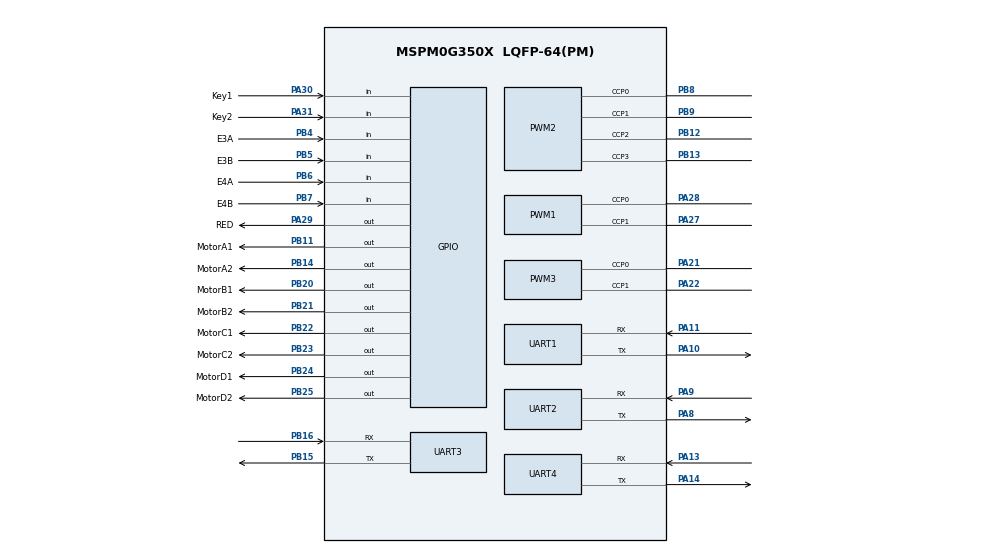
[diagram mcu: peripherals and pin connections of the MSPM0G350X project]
/**
 * @cliArgs --device "MSPM0G350X" --package "LQFP-64(PM)" --part "Default" --product "mspm0_sdk@2.01.00.03"
 * @versions {"tool":"1.20.0+3587"}
 */

/**
 * Import the modules used in this configuration.
 */
const GPIO    = scripting.addModule("/ti/driverlib/GPIO", {}, false);
const GPIO1   = GPIO.addInstance();
const GPIO2   = GPIO.addInstance();
const GPIO3   = GPIO.addInstance();
const GPIO4   = GPIO.addInstance();
const GPIO5   = GPIO.addInstance();
const GPIO6   = GPIO.addInstance();
const GPIO7   = GPIO.addInstance();
const PWM     = scripting.addModule("/ti/driverlib/PWM", {}, false);
const PWM1    = PWM.addInstance();
const PWM2    = PWM.addInstance();
const PWM3    = PWM.addInstance();
const SYSCTL  = scripting.addModule("/ti/driverlib/SYSCTL");
const SYSTICK = scripting.addModule("/ti/driverlib/SYSTICK");
const TIMER   = scripting.addModule("/ti/driverlib/TIMER", {}, false);
const TIMER1  = TIMER.addInstance();
const UART    = scripting.addModule("/ti/driverlib/UART", {}, false);
const UART1   = UART.addInstance();
const UART2   = UART.addInstance();
const UART3   = UART.addInstance();
const UART4   = UART.addInstance();

/**
 * Write custom configuration values to the imported modules.
 */
const divider9       = system.clockTree["UDIV"];
divider9.divideValue = 2;

const gate7  = system.clockTree["MFCLKGATE"];
gate7.enable = true;

const mux4       = system.clockTree["EXHFMUX"];
mux4.inputSelect = "EXHFMUX_XTAL";

const mux8       = system.clockTree["HSCLKMUX"];
mux8.inputSelect = "HSCLKMUX_SYSPLL2X";

const mux12       = system.clockTree["SYSPLLMUX"];
mux12.inputSelect = "zSYSPLLMUX_HFCLK";

const pinFunction4        = system.clockTree["HFXT"];
pinFunction4.inputFreq    = 40;
pinFunction4.enable       = true;
pinFunction4.HFXTStartup  = 10;
pinFunction4.HFCLKMonitor = true;

GPIO1.$name                          = "GPIO_RGB";
GPIO1.port                           = "PORTA";
GPIO1.associatedPins[0].$name        = "RED";
GPIO1.associatedPins[0].initialValue = "SET";
GPIO1.associatedPins[0].assignedPin  = "29";
GPIO1.associatedPins[0].pin.$assign  = "PA29";

const Board = scripting.addModule("/ti/driverlib/Board", {}, false);

GPIO2.$name                         = "OLED";
GPIO2.port                          = "PORTA";
GPIO2.associatedPins.create(2);
GPIO2.associatedPins[0].$name       = "OLED_SCL";
GPIO2.associatedPins[0].assignedPin = "16";
GPIO2.associatedPins[1].$name       = "OLED_SDA";
GPIO2.associatedPins[1].assignedPin = "15";

GPIO3.$name                         = "Motor";
GPIO3.port                          = "PORTB";
GPIO3.associatedPins.create(8);
GPIO3.associatedPins[0].$name       = "MotorA1";
GPIO3.associatedPins[0].assignedPin = "11";
GPIO3.associatedPins[0].pin.$assign = "PB11";
GPIO3.associatedPins[1].$name       = "MotorA2";
GPIO3.associatedPins[1].assignedPin = "14";
GPIO3.associatedPins[1].pin.$assign = "PB14";
GPIO3.associatedPins[2].$name       = "MotorC1";
GPIO3.associatedPins[2].assignedPin = "22";
GPIO3.associatedPins[2].pin.$assign = "PB22";
GPIO3.associatedPins[3].$name       = "MotorB2";
GPIO3.associatedPins[3].assignedPin = "21";
GPIO3.associatedPins[3].pin.$assign = "PB21";
GPIO3.associatedPins[4].$name       = "MotorB1";
GPIO3.associatedPins[4].assignedPin = "20";
GPIO3.associatedPins[4].pin.$assign = "PB20";
GPIO3.associatedPins[5].$name       = "MotorC2";
GPIO3.associatedPins[5].assignedPin = "23";
GPIO3.associatedPins[5].pin.$assign = "PB23";
GPIO3.associatedPins[6].$name       = "MotorD1";
GPIO3.associatedPins[6].assignedPin = "24";
GPIO3.associatedPins[6].pin.$assign = "PB24";
GPIO3.associatedPins[7].$name       = "MotorD2";
GPIO3.associatedPins[7].assignedPin = "25";
GPIO3.associatedPins[7].pin.$assign = "PB25";

GPIO4.$name                               = "ENCODER";
GPIO4.port                                = "PORTB";
GPIO4.associatedPins.create(4);
GPIO4.associatedPins[0].direction         = "INPUT";
GPIO4.associatedPins[0].interruptEn       = true;
GPIO4.associatedPins[0].interruptPriority = "0";
GPIO4.associatedPins[0].polarity          = "RISE";
GPIO4.associatedPins[0].$name             = "E3A";
GPIO4.associatedPins[0].assignedPin       = "4";
GPIO4.associatedPins[0].internalResistor  = "PULL_UP";
GPIO4.associatedPins[0].pin.$assign       = "PB4";
GPIO4.associatedPins[1].$name             = "E3B";
GPIO4.associatedPins[1].direction         = "INPUT";
GPIO4.associatedPins[1].interruptEn       = true;
GPIO4.associatedPins[1].interruptPriority = "0";
GPIO4.associatedPins[1].polarity          = "RISE";
GPIO4.associatedPins[1].assignedPin       = "5";
GPIO4.associatedPins[1].internalResistor  = "PULL_UP";
GPIO4.associatedPins[1].pin.$assign       = "PB5";
GPIO4.associatedPins[2].$name             = "E4A";
GPIO4.associatedPins[2].direction         = "INPUT";
GPIO4.associatedPins[2].assignedPin       = "6";
GPIO4.associatedPins[2].interruptEn       = true;
GPIO4.associatedPins[2].interruptPriority = "0";
GPIO4.associatedPins[2].polarity          = "RISE";
GPIO4.associatedPins[2].internalResistor  = "PULL_UP";
GPIO4.associatedPins[2].pin.$assign       = "PB6";
GPIO4.associatedPins[3].$name             = "E4B";
GPIO4.associatedPins[3].direction         = "INPUT";
GPIO4.associatedPins[3].assignedPin       = "7";
GPIO4.associatedPins[3].interruptEn       = true;
GPIO4.associatedPins[3].interruptPriority = "0";
GPIO4.associatedPins[3].polarity          = "RISE";
GPIO4.associatedPins[3].internalResistor  = "PULL_UP";
GPIO4.associatedPins[3].pin.$assign       = "PB7";

GPIO5.$name                              = "sensor";
GPIO5.associatedPins.create(8);
GPIO5.associatedPins[0].$name            = "D1";
GPIO5.associatedPins[0].direction        = "INPUT";
GPIO5.associatedPins[0].assignedPort     = "PORTB";
GPIO5.associatedPins[0].assignedPin      = "0";
GPIO5.associatedPins[0].internalResistor = "PULL_DOWN";
GPIO5.associatedPins[1].$name            = "D2";
GPIO5.associatedPins[1].assignedPort     = "PORTB";
GPIO5.associatedPins[1].assignedPin      = "27";
GPIO5.associatedPins[1].direction        = "INPUT";
GPIO5.associatedPins[1].internalResistor = "PULL_DOWN";
GPIO5.associatedPins[2].$name            = "D3";
GPIO5.associatedPins[2].direction        = "INPUT";
GPIO5.associatedPins[2].assignedPort     = "PORTB";
GPIO5.associatedPins[2].assignedPin      = "26";
GPIO5.associatedPins[2].internalResistor = "PULL_DOWN";
GPIO5.associatedPins[3].$name            = "D4";
GPIO5.associatedPins[3].direction        = "INPUT";
GPIO5.associatedPins[3].assignedPort     = "PORTA";
GPIO5.associatedPins[3].assignedPin      = "26";
GPIO5.associatedPins[3].internalResistor = "PULL_DOWN";
GPIO5.associatedPins[4].$name            = "D5";
GPIO5.associatedPins[4].direction        = "INPUT";
GPIO5.associatedPins[4].assignedPort     = "PORTA";
GPIO5.associatedPins[4].assignedPin      = "25";
GPIO5.associatedPins[4].internalResistor = "PULL_DOWN";
GPIO5.associatedPins[5].$name            = "D6";
GPIO5.associatedPins[5].direction        = "INPUT";
GPIO5.associatedPins[5].assignedPort     = "PORTA";
GPIO5.associatedPins[5].assignedPin      = "24";
GPIO5.associatedPins[5].internalResistor = "PULL_DOWN";
GPIO5.associatedPins[6].$name            = "D7";
GPIO5.associatedPins[6].direction        = "INPUT";
GPIO5.associatedPins[6].assignedPort     = "PORTA";
GPIO5.associatedPins[6].assignedPin      = "12";
GPIO5.associatedPins[6].internalResistor = "PULL_DOWN";
GPIO5.associatedPins[7].$name            = "D8";
GPIO5.associatedPins[7].direction        = "INPUT";
GPIO5.associatedPins[7].assignedPort     = "PORTA";
GPIO5.associatedPins[7].assignedPin      = "7";
GPIO5.associatedPins[7].internalResistor = "PULL_DOWN";

GPIO6.$name                              = "Key";
GPIO6.associatedPins.create(6);
GPIO6.associatedPins[0].$name            = "Key1";
GPIO6.associatedPins[0].direction        = "INPUT";
GPIO6.associatedPins[0].internalResistor = "PULL_UP";
GPIO6.associatedPins[0].assignedPin      = "30";
GPIO6.associatedPins[0].pin.$assign      = "PA30";
GPIO6.associatedPins[1].$name            = "Key2";
GPIO6.associatedPins[1].direction        = "INPUT";
GPIO6.associatedPins[1].assignedPin      = "31";
GPIO6.associatedPins[1].internalResistor = "PULL_UP";
GPIO6.associatedPins[1].pin.$assign      = "PA31";
GPIO6.associatedPins[2].$name            = "key3";
GPIO6.associatedPins[2].direction        = "INPUT";
GPIO6.associatedPins[2].internalResistor = "PULL_UP";
GPIO6.associatedPins[2].assignedPort     = "PORTB";
GPIO6.associatedPins[2].assignedPin      = "10";
GPIO6.associatedPins[3].$name            = "key4";
GPIO6.associatedPins[3].direction        = "INPUT";
GPIO6.associatedPins[3].internalResistor = "PULL_UP";
GPIO6.associatedPins[3].assignedPort     = "PORTB";
GPIO6.associatedPins[3].assignedPin      = "17";
GPIO6.associatedPins[4].$name            = "key5";
GPIO6.associatedPins[4].direction        = "INPUT";
GPIO6.associatedPins[4].assignedPort     = "PORTB";
GPIO6.associatedPins[4].assignedPin      = "18";
GPIO6.associatedPins[4].internalResistor = "PULL_UP";
GPIO6.associatedPins[5].$name            = "key6";
GPIO6.associatedPins[5].direction        = "INPUT";
GPIO6.associatedPins[5].internalResistor = "PULL_UP";
GPIO6.associatedPins[5].assignedPort     = "PORTB";
GPIO6.associatedPins[5].assignedPin      = "19";

GPIO7.$name                         = "BUZZER";
GPIO7.port                          = "PORTA";
GPIO7.associatedPins[0].$name       = "buzzer";
GPIO7.associatedPins[0].assignedPin = "2";

PWM1.$name                              = "PWM";
PWM1.timerStartTimer                    = true;
PWM1.clockDivider                       = 8;
PWM1.timerCount                         = 20000;
PWM1.peripheral.$assign                 = "TIMG7";
PWM1.peripheral.ccp0Pin.$assign         = "PA28";
PWM1.peripheral.ccp1Pin.$assign         = "PA27";
PWM1.PWM_CHANNEL_0.$name                = "ti_driverlib_pwm_PWMTimerCC0";
PWM1.PWM_CHANNEL_0.invert               = true;
PWM1.PWM_CHANNEL_1.$name                = "ti_driverlib_pwm_PWMTimerCC1";
PWM1.PWM_CHANNEL_1.invert               = true;
PWM1.ccp0PinConfig.$name                = "ti_driverlib_gpio_GPIOPinGeneric0";
PWM1.ccp0PinConfig.direction            = scripting.forceWrite("OUTPUT");
PWM1.ccp0PinConfig.hideOutputInversion  = scripting.forceWrite(false);
PWM1.ccp0PinConfig.onlyInternalResistor = scripting.forceWrite(false);
PWM1.ccp0PinConfig.passedPeripheralType = scripting.forceWrite("Digital");
PWM1.ccp1PinConfig.$name                = "ti_driverlib_gpio_GPIOPinGeneric1";
PWM1.ccp1PinConfig.direction            = scripting.forceWrite("OUTPUT");
PWM1.ccp1PinConfig.hideOutputInversion  = scripting.forceWrite(false);
PWM1.ccp1PinConfig.onlyInternalResistor = scripting.forceWrite(false);
PWM1.ccp1PinConfig.passedPeripheralType = scripting.forceWrite("Digital");

PWM2.$name                              = "Motor_PWM";
PWM2.ccIndex                            = [0,1,2,3];
PWM2.clockDivider                       = 8;
PWM2.clockPrescale                      = 2;
PWM2.timerStartTimer                    = true;
PWM2.peripheral.$assign                 = "TIMA0";
PWM2.peripheral.ccp0Pin.$assign         = "PB8";
PWM2.peripheral.ccp1Pin.$assign         = "PB9";
PWM2.peripheral.ccp2Pin.$assign         = "PB12";
PWM2.peripheral.ccp3Pin.$assign         = "PB13";
PWM2.PWM_CHANNEL_0.$name                = "ti_driverlib_pwm_PWMTimerCC2";
PWM2.PWM_CHANNEL_0.invert               = true;
PWM2.PWM_CHANNEL_1.$name                = "ti_driverlib_pwm_PWMTimerCC3";
PWM2.PWM_CHANNEL_1.invert               = true;
PWM2.ccp0PinConfig.direction            = scripting.forceWrite("OUTPUT");
PWM2.ccp0PinConfig.hideOutputInversion  = scripting.forceWrite(false);
PWM2.ccp0PinConfig.onlyInternalResistor = scripting.forceWrite(false);
PWM2.ccp0PinConfig.passedPeripheralType = scripting.forceWrite("Digital");
PWM2.ccp0PinConfig.$name                = "ti_driverlib_gpio_GPIOPinGeneric10";
PWM2.ccp1PinConfig.direction            = scripting.forceWrite("OUTPUT");
PWM2.ccp1PinConfig.hideOutputInversion  = scripting.forceWrite(false);
PWM2.ccp1PinConfig.onlyInternalResistor = scripting.forceWrite(false);
PWM2.ccp1PinConfig.passedPeripheralType = scripting.forceWrite("Digital");
PWM2.ccp1PinConfig.$name                = "ti_driverlib_gpio_GPIOPinGeneric11";
PWM2.PWM_CHANNEL_2.$name                = "ti_driverlib_pwm_PWMTimerCC4";
PWM2.PWM_CHANNEL_2.invert               = true;
PWM2.PWM_CHANNEL_3.$name                = "ti_driverlib_pwm_PWMTimerCC5";
PWM2.PWM_CHANNEL_3.invert               = true;
PWM2.ccp2PinConfig.$name                = "ti_driverlib_gpio_GPIOPinGeneric12";
PWM2.ccp3PinConfig.$name                = "ti_driverlib_gpio_GPIOPinGeneric13";

PWM3.$name                              = "Servo_PWM";
PWM3.clockDivider                       = 8;
PWM3.timerStartTimer                    = true;
PWM3.timerCount                         = 20000;
PWM3.peripheral.$assign                 = "TIMG6";
PWM3.peripheral.ccp0Pin.$assign         = "PA21";
PWM3.peripheral.ccp1Pin.$assign         = "PA22";
PWM3.PWM_CHANNEL_0.$name                = "ti_driverlib_pwm_PWMTimerCC6";
PWM3.PWM_CHANNEL_0.invert               = true;
PWM3.PWM_CHANNEL_1.$name                = "ti_driverlib_pwm_PWMTimerCC7";
PWM3.PWM_CHANNEL_1.invert               = true;
PWM3.ccp0PinConfig.direction            = scripting.forceWrite("OUTPUT");
PWM3.ccp0PinConfig.hideOutputInversion  = scripting.forceWrite(false);
PWM3.ccp0PinConfig.onlyInternalResistor = scripting.forceWrite(false);
PWM3.ccp0PinConfig.passedPeripheralType = scripting.forceWrite("Digital");
PWM3.ccp0PinConfig.$name                = "ti_driverlib_gpio_GPIOPinGeneric14";
PWM3.ccp1PinConfig.direction            = scripting.forceWrite("OUTPUT");
PWM3.ccp1PinConfig.hideOutputInversion  = scripting.forceWrite(false);
PWM3.ccp1PinConfig.onlyInternalResistor = scripting.forceWrite(false);
PWM3.ccp1PinConfig.passedPeripheralType = scripting.forceWrite("Digital");
PWM3.ccp1PinConfig.$name                = "ti_driverlib_gpio_GPIOPinGeneric15";

SYSCTL.forceDefaultClkConfig = true;
SYSCTL.clockTreeEn           = true;

SYSTICK.periodEnable      = true;
SYSTICK.interruptEnable   = true;
SYSTICK.interruptPriority = "0";
SYSTICK.systickEnable     = true;
SYSTICK.period            = 80000;

TIMER1.$name              = "TIMER_0";
TIMER1.timerClkDiv        = 8;
TIMER1.interrupts         = ["ZERO"];
TIMER1.timerMode          = "PERIODIC_UP";
TIMER1.timerPeriod        = "10 ms";
TIMER1.peripheral.$assign = "TIMG0";

UART1.$name                            = "UART_Debug";
UART1.targetBaudRate                   = 115200;
UART1.enabledInterrupts                = ["RX"];
UART1.peripheral.rxPin.$assign         = "PA11";
UART1.peripheral.txPin.$assign         = "PA10";
UART1.txPinConfig.direction            = scripting.forceWrite("OUTPUT");
UART1.txPinConfig.hideOutputInversion  = scripting.forceWrite(false);
UART1.txPinConfig.onlyInternalResistor = scripting.forceWrite(false);
UART1.txPinConfig.passedPeripheralType = scripting.forceWrite("Digital");
UART1.txPinConfig.$name                = "ti_driverlib_gpio_GPIOPinGeneric2";
UART1.rxPinConfig.hideOutputInversion  = scripting.forceWrite(false);
UART1.rxPinConfig.onlyInternalResistor = scripting.forceWrite(false);
UART1.rxPinConfig.passedPeripheralType = scripting.forceWrite("Digital");
UART1.rxPinConfig.$name                = "ti_driverlib_gpio_GPIOPinGeneric3";

UART2.$name                            = "UART1";
UART2.targetBaudRate                   = 115200;
UART2.enabledInterrupts                = ["RX"];
UART2.peripheral.$assign               = "UART1";
UART2.peripheral.rxPin.$assign         = "PA9";
UART2.peripheral.txPin.$assign         = "PA8";
UART2.txPinConfig.direction            = scripting.forceWrite("OUTPUT");
UART2.txPinConfig.hideOutputInversion  = scripting.forceWrite(false);
UART2.txPinConfig.onlyInternalResistor = scripting.forceWrite(false);
UART2.txPinConfig.passedPeripheralType = scripting.forceWrite("Digital");
UART2.txPinConfig.$name                = "ti_driverlib_gpio_GPIOPinGeneric4";
UART2.rxPinConfig.hideOutputInversion  = scripting.forceWrite(false);
UART2.rxPinConfig.onlyInternalResistor = scripting.forceWrite(false);
UART2.rxPinConfig.passedPeripheralType = scripting.forceWrite("Digital");
UART2.rxPinConfig.$name                = "ti_driverlib_gpio_GPIOPinGeneric5";

UART3.$name                            = "UART2";
UART3.targetBaudRate                   = 115200;
UART3.enabledInterrupts                = ["RX"];
UART3.peripheral.$assign               = "UART2";
UART3.peripheral.rxPin.$assign         = "PB16";
UART3.peripheral.txPin.$assign         = "PB15";
UART3.txPinConfig.direction            = scripting.forceWrite("OUTPUT");
UART3.txPinConfig.hideOutputInversion  = scripting.forceWrite(false);
UART3.txPinConfig.onlyInternalResistor = scripting.forceWrite(false);
UART3.txPinConfig.passedPeripheralType = scripting.forceWrite("Digital");
UART3.txPinConfig.$name                = "ti_driverlib_gpio_GPIOPinGeneric6";
UART3.rxPinConfig.hideOutputInversion  = scripting.forceWrite(false);
UART3.rxPinConfig.onlyInternalResistor = scripting.forceWrite(false);
UART3.rxPinConfig.passedPeripheralType = scripting.forceWrite("Digital");
UART3.rxPinConfig.$name                = "ti_driverlib_gpio_GPIOPinGeneric7";

UART4.targetBaudRate                       = 115200;
UART4.$name                                = "UART_JY901S";
UART4.enabledDMARXTriggers                 = "DL_UART_DMA_INTERRUPT_RX";
UART4.peripheral.$assign                   = "UART3";
UART4.peripheral.rxPin.$assign             = "PA13";
UART4.peripheral.txPin.$assign             = "PA14";
UART4.txPinConfig.direction                = scripting.forceWrite("OUTPUT");
UART4.txPinConfig.hideOutputInversion      = scripting.forceWrite(false);
UART4.txPinConfig.onlyInternalResistor     = scripting.forceWrite(false);
UART4.txPinConfig.passedPeripheralType     = scripting.forceWrite("Digital");
UART4.txPinConfig.$name                    = "ti_driverlib_gpio_GPIOPinGeneric8";
UART4.rxPinConfig.hideOutputInversion      = scripting.forceWrite(false);
UART4.rxPinConfig.onlyInternalResistor     = scripting.forceWrite(false);
UART4.rxPinConfig.passedPeripheralType     = scripting.forceWrite("Digital");
UART4.rxPinConfig.internalResistor         = "PULL_UP";
UART4.rxPinConfig.enableConfig             = true;
UART4.rxPinConfig.$name                    = "ti_driverlib_gpio_GPIOPinGeneric9";
UART4.DMA_CHANNEL_RX.$name                 = "DMA_UART_JY901S";
UART4.DMA_CHANNEL_RX.addressMode           = "f2b";
UART4.DMA_CHANNEL_RX.srcLength             = "BYTE";
UART4.DMA_CHANNEL_RX.dstLength             = "BYTE";
UART4.DMA_CHANNEL_RX.configureTransferSize = true;
UART4.DMA_CHANNEL_RX.transferSize          = 66;
UART4.DMA_CHANNEL_RX.transferMode          = "FULL_CH_REPEAT_SINGLE";
UART4.DMA_CHANNEL_RX.destIncrement         = "INCREMENT";
UART4.DMA_CHANNEL_RX.peripheral.$assign    = "DMA_CH0";

/**
 * Pinmux solution for unlocked pins/peripherals. This ensures that minor changes to the automatic solver in a future
 * version of the tool will not impact the pinmux you originally saw.  These lines can be completely deleted in order to
 * re-solve from scratch.
 */
pinFunction4.peripheral.$suggestSolution           = "SYSCTL";
pinFunction4.peripheral.hfxInPin.$suggestSolution  = "PA5";
pinFunction4.peripheral.hfxOutPin.$suggestSolution = "PA6";
Board.peripheral.$suggestSolution                  = "DEBUGSS";
Board.peripheral.swclkPin.$suggestSolution         = "PA20";
Board.peripheral.swdioPin.$suggestSolution         = "PA19";
GPIO2.associatedPins[0].pin.$suggestSolution       = "PA16";
GPIO2.associatedPins[1].pin.$suggestSolution       = "PA15";
GPIO5.associatedPins[0].pin.$suggestSolution       = "PB0";
GPIO5.associatedPins[1].pin.$suggestSolution       = "PB27";
GPIO5.associatedPins[2].pin.$suggestSolution       = "PB26";
GPIO5.associatedPins[3].pin.$suggestSolution       = "PA26";
GPIO5.associatedPins[4].pin.$suggestSolution       = "PA25";
GPIO5.associatedPins[5].pin.$suggestSolution       = "PA24";
GPIO5.associatedPins[6].pin.$suggestSolution       = "PA12";
GPIO5.associatedPins[7].pin.$suggestSolution       = "PA7";
GPIO6.associatedPins[2].pin.$suggestSolution       = "PB10";
GPIO6.associatedPins[3].pin.$suggestSolution       = "PB17";
GPIO6.associatedPins[4].pin.$suggestSolution       = "PB18";
GPIO6.associatedPins[5].pin.$suggestSolution       = "PB19";
GPIO7.associatedPins[0].pin.$suggestSolution       = "PA2";
UART1.peripheral.$suggestSolution                  = "UART0";
